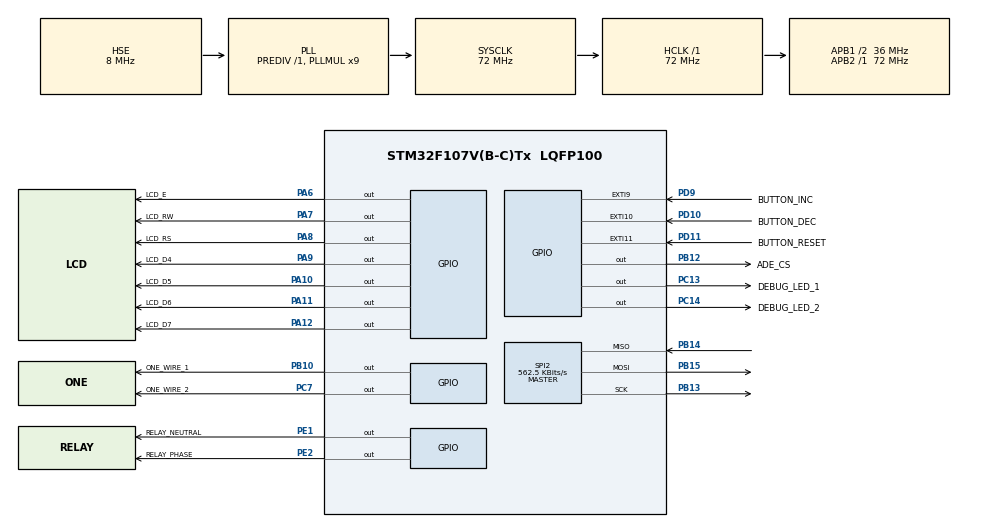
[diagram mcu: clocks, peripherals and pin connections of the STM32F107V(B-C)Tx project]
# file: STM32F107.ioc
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Mcu.Family=STM32F1
Mcu.Name=STM32F107V(B-C)Tx
Mcu.Package=LQFP100
NVIC.EXTI15_10_IRQn=true\:5\:0\:false\:false\:true\:true\:true
NVIC.EXTI9_5_IRQn=true\:5\:0\:false\:false\:true\:true\:true
NVIC.PriorityGroup=NVIC_PRIORITYGROUP_4
OSC_IN.Mode=HSE-External-Oscillator
OSC_IN.Signal=RCC_OSC_IN
OSC_OUT.Mode=HSE-External-Oscillator
OSC_OUT.Signal=RCC_OSC_OUT
PA13.Mode=Serial_Wire
PA13.Signal=SYS_JTMS-SWDIO
PA14.Mode=Serial_Wire
PA14.Signal=SYS_JTCK-SWCLK
PA6.GPIO_Label=LCD_E
PA6.GPIO_OutputLevel=GPIO_PIN_RESET
PA6.GPIO_Speed=GPIO_SPEED_FREQ_LOW
PA6.Signal=GPIO_Output
PA7.GPIO_Label=LCD_RW
PA7.GPIO_OutputLevel=GPIO_PIN_RESET
PA7.GPIO_Speed=GPIO_SPEED_FREQ_LOW
PA7.Signal=GPIO_Output
PA8.GPIO_Label=LCD_RS
PA8.GPIO_OutputLevel=GPIO_PIN_RESET
PA8.GPIO_Speed=GPIO_SPEED_FREQ_LOW
PA8.Signal=GPIO_Output
PA9.GPIO_Label=LCD_D4
PA9.GPIO_OutputLevel=GPIO_PIN_RESET
PA9.GPIO_Speed=GPIO_SPEED_FREQ_LOW
PA9.Signal=GPIO_Output
PA10.GPIO_Label=LCD_D5
PA10.GPIO_OutputLevel=GPIO_PIN_RESET
PA10.GPIO_Speed=GPIO_SPEED_FREQ_LOW
PA10.Signal=GPIO_Output
PA11.GPIO_Label=LCD_D6
PA11.GPIO_OutputLevel=GPIO_PIN_RESET
PA11.GPIO_Speed=GPIO_SPEED_FREQ_LOW
PA11.Signal=GPIO_Output
PA12.GPIO_Label=LCD_D7
PA12.GPIO_OutputLevel=GPIO_PIN_RESET
PA12.GPIO_Speed=GPIO_SPEED_FREQ_LOW
PA12.Signal=GPIO_Output
PB10.GPIO_Label=ONE_WIRE_1
PB10.GPIO_ModeDefaultOutputPP=GPIO_MODE_OUTPUT_OD
PB10.GPIO_OutputLevel=GPIO_PIN_SET
PB10.GPIO_PuPd=GPIO_NOPULL
PB10.GPIO_Speed=GPIO_SPEED_FREQ_HIGH
PB10.Signal=GPIO_Output
PB12.GPIO_Label=ADE_CS
PB12.GPIO_OutputLevel=GPIO_PIN_SET
PB12.GPIO_Speed=GPIO_SPEED_FREQ_HIGH
PB12.Signal=GPIO_Output
PB13.Mode=Full_Duplex_Master
PB13.Signal=SPI2_SCK
PB14.Mode=Full_Duplex_Master
PB14.Signal=SPI2_MISO
PB15.Mode=Full_Duplex_Master
PB15.Signal=SPI2_MOSI
PC7.GPIO_Label=ONE_WIRE_2
PC7.GPIO_ModeDefaultOutputPP=GPIO_MODE_OUTPUT_OD
PC7.GPIO_OutputLevel=GPIO_PIN_SET
PC7.GPIO_PuPd=GPIO_NOPULL
PC7.GPIO_Speed=GPIO_SPEED_FREQ_HIGH
PC7.Signal=GPIO_Output
PC13.GPIO_Label=DEBUG_LED_1
PC13.GPIO_OutputLevel=GPIO_PIN_SET
PC13.Signal=GPIO_Output
PC14.GPIO_Label=DEBUG_LED_2
PC14.GPIO_OutputLevel=GPIO_PIN_SET
PC14.Signal=GPIO_Output
PD9.GPIO_Label=BUTTON_INC
PD9.GPIO_PuPd=GPIO_NOPULL
PD9.Signal=GPXTI9
PD10.GPIO_Label=BUTTON_DEC
PD10.GPIO_PuPd=GPIO_NOPULL
PD10.Signal=GPXTI10
PD11.GPIO_Label=BUTTON_RESET
PD11.GPIO_PuPd=GPIO_NOPULL
PD11.Signal=GPXTI11
ProjectManager.HeapSize=0x200
ProjectManager.StackSize=0x400
ProjectManager.TargetToolchain=MDK-ARM V5
RCC.AHBFreq_Value=72000000
RCC.APB1CLKDivider=RCC_HCLK_DIV2
RCC.APB1Freq_Value=36000000
RCC.APB1TimFreq_Value=72000000
RCC.APB2Freq_Value=72000000
RCC.APB2TimFreq_Value=72000000
RCC.HCLKFreq_Value=72000000
RCC.PLLMUL=RCC_PLL_MUL9
RCC.PLLSourceVirtual=RCC_PLLSOURCE_HSE
RCC.SYSCLKFreq_VALUE=72000000
RCC.SYSCLKSource=RCC_SYSCLKSOURCE_PLLCLK
RCC.USBFreq_Value=48000000
SPI2.BaudRatePrescaler=SPI_BAUDRATEPRESCALER_64
SPI2.CLKPhase=SPI_PHASE_2EDGE
SPI2.CLKPolarity=SPI_POLARITY_HIGH
SPI2.CalculateBaudRate=562.5 KBits/s
SPI2.Direction=SPI_DIRECTION_2LINES
SPI2.Mode=SPI_MODE_MASTER
SPI2.VirtualType=VM_MASTER
board=custom
PE1.GPIO_Label=RELAY_NEUTRAL
PE1.GPIO_OutputLevel=GPIO_PIN_SET
PE1.GPIO_Speed=GPIO_SPEED_FREQ_LOW
PE1.Signal=GPIO_Output
PE2.GPIO_Label=RELAY_PHASE
PE2.GPIO_OutputLevel=GPIO_PIN_SET
PE2.GPIO_Speed=GPIO_SPEED_FREQ_LOW
PE2.Signal=GPIO_Output

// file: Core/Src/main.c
/* USER CODE BEGIN Header */
/**
  ******************************************************************************
  * @file           : main.c
  * @brief          : Main program body
  ******************************************************************************
  * @attention
  *
  * Copyright (c) 2021 STMicroelectronics.
  * All rights reserved.
  *
  * This software is licensed under terms found in the LICENSE file in the
  * root directory of this software component. If no LICENSE file comes with
  * this software, it is provided AS-IS.
  *
  ******************************************************************************
  */
/* USER CODE END Header */

#include "main.h"

/* USER CODE BEGIN Includes */
#include "app.h"
#include "diagnostic_led.h"
/* USER CODE END Includes */

void SystemClock_Config(void);
static void MX_GPIO_Init(void);
static void MX_SPI2_Init(void);

SPI_HandleTypeDef hspi2;

int main(void)
{
  HAL_Init();
  SystemClock_Config();
  MX_GPIO_Init();
  MX_SPI2_Init();

  /* USER CODE BEGIN 2 */
  /* Bind the portable ADE7880 driver after CubeMX initializes SPI2 and GPIO. */
  App_Init(&hspi2);
  /* USER CODE END 2 */

  /* USER CODE BEGIN WHILE */
  while (1)
  {
    /* Keep this cooperative service running; it samples ADE7880 once/second. */
    App_Process();
    /* USER CODE END WHILE */
  }
}

/**
  * @brief Configure SPI2 for the ADE7880 (mode 3, 562.5 kbit/s).
  */
static void MX_SPI2_Init(void)
{
  hspi2.Instance = SPI2;
  hspi2.Init.Mode = SPI_MODE_MASTER;
  hspi2.Init.Direction = SPI_DIRECTION_2LINES;
  hspi2.Init.DataSize = SPI_DATASIZE_8BIT;
  hspi2.Init.CLKPolarity = SPI_POLARITY_HIGH;
  hspi2.Init.CLKPhase = SPI_PHASE_2EDGE;
  hspi2.Init.NSS = SPI_NSS_SOFT;
  hspi2.Init.BaudRatePrescaler = SPI_BAUDRATEPRESCALER_64;
  hspi2.Init.FirstBit = SPI_FIRSTBIT_MSB;
  hspi2.Init.TIMode = SPI_TIMODE_DISABLE;
  hspi2.Init.CRCCalculation = SPI_CRCCALCULATION_DISABLE;
  hspi2.Init.CRCPolynomial = 10;
  if (HAL_SPI_Init(&hspi2) != HAL_OK)
  {
    Error_Handler();
  }
}

/**
  * @brief Configure the 72 MHz system clock from the 8 MHz external crystal.
  */
void SystemClock_Config(void)
{
  RCC_OscInitTypeDef RCC_OscInitStruct = {0};
  RCC_ClkInitTypeDef RCC_ClkInitStruct = {0};

  RCC_OscInitStruct.OscillatorType = RCC_OSCILLATORTYPE_HSE;
  RCC_OscInitStruct.HSEState = RCC_HSE_ON;
  RCC_OscInitStruct.HSEPredivValue = RCC_HSE_PREDIV_DIV1;
  RCC_OscInitStruct.HSIState = RCC_HSI_ON;
  RCC_OscInitStruct.Prediv1Source = RCC_PREDIV1_SOURCE_HSE;
  RCC_OscInitStruct.PLL.PLLState = RCC_PLL_ON;
  RCC_OscInitStruct.PLL.PLLSource = RCC_PLLSOURCE_HSE;
  RCC_OscInitStruct.PLL.PLLMUL = RCC_PLL_MUL9;
  RCC_OscInitStruct.PLL2.PLL2State = RCC_PLL_NONE;
  if (HAL_RCC_OscConfig(&RCC_OscInitStruct) != HAL_OK)
  {
    Error_Handler();
  }

  RCC_ClkInitStruct.ClockType = RCC_CLOCKTYPE_HCLK | RCC_CLOCKTYPE_SYSCLK |
                                RCC_CLOCKTYPE_PCLK1 | RCC_CLOCKTYPE_PCLK2;
  RCC_ClkInitStruct.SYSCLKSource = RCC_SYSCLKSOURCE_PLLCLK;
  RCC_ClkInitStruct.AHBCLKDivider = RCC_SYSCLK_DIV1;
  RCC_ClkInitStruct.APB1CLKDivider = RCC_HCLK_DIV2;
  RCC_ClkInitStruct.APB2CLKDivider = RCC_HCLK_DIV1;
  if (HAL_RCC_ClockConfig(&RCC_ClkInitStruct, FLASH_LATENCY_2) != HAL_OK)
  {
    Error_Handler();
  }
}

/** Configure LEDs, ADE7880 chip select, and two open-drain 1-Wire buses. */
static void MX_GPIO_Init(void)
{
  GPIO_InitTypeDef GPIO_InitStruct = {0};

  __HAL_RCC_GPIOC_CLK_ENABLE();
  __HAL_RCC_GPIOB_CLK_ENABLE();
  __HAL_RCC_GPIOA_CLK_ENABLE();
  __HAL_RCC_GPIOD_CLK_ENABLE();
  HAL_GPIO_WritePin(GPIOC, ONE_WIRE_2_Pin | GPIO_PIN_13 | GPIO_PIN_14,
                    GPIO_PIN_SET);
  HAL_GPIO_WritePin(GPIOB, ONE_WIRE_1_Pin | ADE_CS_Pin, GPIO_PIN_SET);
  HAL_GPIO_WritePin(GPIOA, LCD_E_Pin | LCD_RW_Pin | LCD_RS_Pin |
                    LCD_D4_Pin | LCD_D5_Pin | LCD_D6_Pin | LCD_D7_Pin,
                    GPIO_PIN_RESET);

  GPIO_InitStruct.Pin = LCD_E_Pin | LCD_RW_Pin | LCD_RS_Pin |
                        LCD_D4_Pin | LCD_D5_Pin | LCD_D6_Pin | LCD_D7_Pin;
  GPIO_InitStruct.Mode = GPIO_MODE_OUTPUT_PP;
  GPIO_InitStruct.Pull = GPIO_NOPULL;
  GPIO_InitStruct.Speed = GPIO_SPEED_FREQ_LOW;
  HAL_GPIO_Init(GPIOA, &GPIO_InitStruct);

  GPIO_InitStruct.Pin = BUTTON_INC_Pin | BUTTON_DEC_Pin | BUTTON_RESET_Pin;
  GPIO_InitStruct.Mode = GPIO_MODE_IT_RISING;
  GPIO_InitStruct.Pull = GPIO_NOPULL;
  HAL_GPIO_Init(GPIOD, &GPIO_InitStruct);

  GPIO_InitStruct.Pin = GPIO_PIN_13 | GPIO_PIN_14;
  GPIO_InitStruct.Mode = GPIO_MODE_OUTPUT_PP;
  GPIO_InitStruct.Pull = GPIO_NOPULL;
  GPIO_InitStruct.Speed = GPIO_SPEED_FREQ_LOW;
  HAL_GPIO_Init(GPIOC, &GPIO_InitStruct);

  GPIO_InitStruct.Pin = ADE_CS_Pin;
  GPIO_InitStruct.Mode = GPIO_MODE_OUTPUT_PP;
  GPIO_InitStruct.Pull = GPIO_NOPULL;
  GPIO_InitStruct.Speed = GPIO_SPEED_FREQ_HIGH;
  HAL_GPIO_Init(ADE_CS_GPIO_Port, &GPIO_InitStruct);

  GPIO_InitStruct.Pin = ONE_WIRE_1_Pin;
  GPIO_InitStruct.Mode = GPIO_MODE_OUTPUT_OD;
  GPIO_InitStruct.Pull = GPIO_NOPULL;
  GPIO_InitStruct.Speed = GPIO_SPEED_FREQ_HIGH;
  HAL_GPIO_Init(ONE_WIRE_1_GPIO_Port, &GPIO_InitStruct);

  GPIO_InitStruct.Pin = ONE_WIRE_2_Pin;
  GPIO_InitStruct.Mode = GPIO_MODE_OUTPUT_OD;
  GPIO_InitStruct.Pull = GPIO_NOPULL;
  GPIO_InitStruct.Speed = GPIO_SPEED_FREQ_HIGH;
  HAL_GPIO_Init(ONE_WIRE_2_GPIO_Port, &GPIO_InitStruct);

  HAL_NVIC_SetPriority(EXTI9_5_IRQn, 5, 0);
  HAL_NVIC_EnableIRQ(EXTI9_5_IRQn);
  HAL_NVIC_SetPriority(EXTI15_10_IRQn, 5, 0);
  HAL_NVIC_EnableIRQ(EXTI15_10_IRQn);
}

void Error_Handler(void)
{
  /* USER CODE BEGIN Error_Handler_Debug */
  DiagnosticLed_Init();
  DiagnosticLed_SetMode(DIAGNOSTIC_LED_MODE_ERROR);
  while (1)
  {
    DiagnosticLed_Process();
  }
  /* USER CODE END Error_Handler_Debug */
}

#ifdef USE_FULL_ASSERT
void assert_failed(uint8_t *file, uint32_t line)
{
  /* USER CODE BEGIN 6 */
  (void)file;
  (void)line;
  /* USER CODE END 6 */
}
#endif
